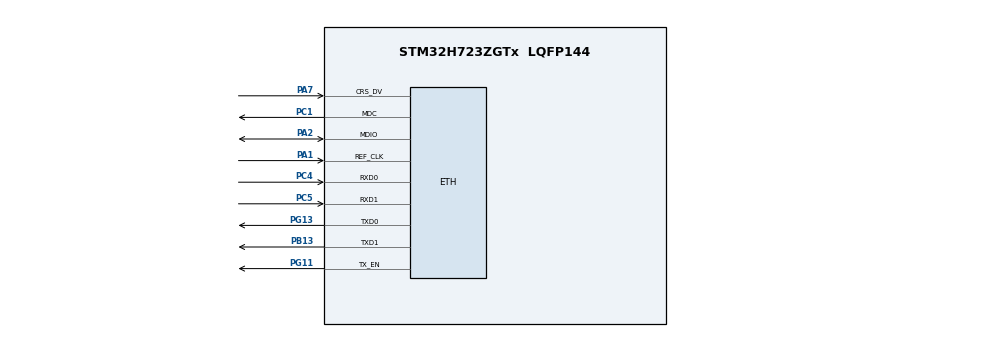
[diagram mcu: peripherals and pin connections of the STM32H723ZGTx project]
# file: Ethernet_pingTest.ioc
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CORTEX_M7.AccessPermission_S-Cortex_Memory_Protection_Unit_Region1_Settings_S=MPU_REGION_FULL_ACCESS
CORTEX_M7.BaseAddress_S-Cortex_Memory_Protection_Unit_Region1_Settings_S=0x30000000
CORTEX_M7.CPU_DCache=Enabled
CORTEX_M7.CPU_ICache=Enabled
CORTEX_M7.DisableExec_S-Cortex_Memory_Protection_Unit_Region1_Settings_S=MPU_INSTRUCTION_ACCESS_DISABLE
CORTEX_M7.Enable_S-Cortex_Memory_Protection_Unit_Region1_Settings_S=MPU_REGION_ENABLE
CORTEX_M7.Enable_Spec=__NULL
CORTEX_M7.IsShareable_S-Cortex_Memory_Protection_Unit_Region1_Settings_S=MPU_ACCESS_SHAREABLE
CORTEX_M7.Size_S-Cortex_Memory_Protection_Unit_Region1_Settings_S=MPU_REGION_SIZE_32KB
CORTEX_M7.TypeExtField_S-Cortex_Memory_Protection_Unit_Region1_Settings_S=MPU_TEX_LEVEL1
CORTEX_M7.default_mode_Activation=1
ETH.MediaInterface=HAL_ETH_RMII_MODE
LWIP.BSP.number=1
LWIP.IP_ADDRESS=192.168.001.020
LWIP.LWIP_DHCP=0
LWIP.NETMASK_ADDRESS=255.255.255.000
LWIP.Version=v2.1.2_Cube
LWIP0.BSP.STBoard=false
LWIP0.BSP.api=BSP_COMPONENT_DRIVER
LWIP0.BSP.component=LAN8742
LWIP0.BSP.instance=LAN8742
LWIP0.BSP.name=Driver_PHY
LWIP0.BSP.semaphore=S_LAN8742
LWIP0.BSP.solution=LAN8742
Mcu.Family=STM32H7
Mcu.Name=STM32H723ZGTx
Mcu.Package=LQFP144
NVIC.ETH_IRQn=true\:0\:0\:false\:false\:true\:true\:true\:true
NVIC.PriorityGroup=NVIC_PRIORITYGROUP_4
PA1.GPIO_Speed=GPIO_SPEED_FREQ_VERY_HIGH
PA1.Mode=RMII
PA1.Signal=ETH_REF_CLK
PA2.GPIO_Speed=GPIO_SPEED_FREQ_VERY_HIGH
PA2.Mode=RMII
PA2.Signal=ETH_MDIO
PA7.GPIO_Speed=GPIO_SPEED_FREQ_VERY_HIGH
PA7.Mode=RMII
PA7.Signal=ETH_CRS_DV
PB0.TagName=LD1
PB13.GPIO_Speed=GPIO_SPEED_FREQ_VERY_HIGH
PB13.Mode=RMII
PB13.Signal=ETH_TXD1
PB14.TagName=LD3
PC1.GPIO_Speed=GPIO_SPEED_FREQ_VERY_HIGH
PC1.Mode=RMII
PC1.Signal=ETH_MDC
PC13.TagName=BUTTON
PC4.GPIO_Speed=GPIO_SPEED_FREQ_VERY_HIGH
PC4.Mode=RMII
PC4.Signal=ETH_RXD0
PC5.GPIO_Speed=GPIO_SPEED_FREQ_VERY_HIGH
PC5.Mode=RMII
PC5.Signal=ETH_RXD1
PD8.TagName=VCP_TX
PD9.TagName=VCP_RX
PE1.TagName=LD2
PG11.GPIO_Speed=GPIO_SPEED_FREQ_VERY_HIGH
PG11.Mode=RMII
PG11.Signal=ETH_TX_EN
PG13.GPIO_Speed=GPIO_SPEED_FREQ_VERY_HIGH
PG13.Mode=RMII
PG13.Signal=ETH_TXD0
ProjectManager.HeapSize=0x200
ProjectManager.StackSize=0x400
ProjectManager.TargetToolchain=STM32CubeIDE
RCC.ADCFreq_Value=608000000
RCC.APB1Freq_Value=128000000
RCC.APB2Freq_Value=128000000
RCC.APB3Freq_Value=128000000
RCC.APB4Freq_Value=128000000
RCC.CortexFreq_Value=256000000
RCC.D1PPRE=RCC_APB3_DIV2
RCC.D2PPRE1=RCC_APB1_DIV2
RCC.D2PPRE2=RCC_APB2_DIV2
RCC.D3PPRE=RCC_APB4_DIV2
RCC.DIVM1=4
RCC.DIVM2=1
RCC.DIVN1=16
RCC.DIVN2=19
RCC.DIVP1=1
RCC.DIVQ1=4
RCC.HCLKFreq_Value=256000000
RCC.HSE_VALUE=8000000
RCC.PLLFRACN=0
RCC.SYSCLKFreq_VALUE=256000000
RCC.SYSCLKSource=RCC_SYSCLKSOURCE_PLLCLK
RCC.USBCLockSelection=RCC_USBCLKSOURCE_HSI48
RCC.USBFreq_Value=48000000
VP_LWIP_VS_Enabled.Mode=Enabled
VP_MEMORYMAP_VS_MEMORYMAP.Mode=CurAppReg
board=NUCLEO-H723ZG

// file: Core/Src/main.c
/* USER CODE BEGIN Header */
/**
  ******************************************************************************
  * @file           : main.c
  * @brief          : Main program body
  ******************************************************************************
  * @attention
  *
  * Copyright (c) 2026 STMicroelectronics.
  * All rights reserved.
  *
  * This software is licensed under terms that can be found in the LICENSE file
  * in the root directory of this software component.
  * If no LICENSE file comes with this software, it is provided AS-IS.
  *
  ******************************************************************************
  */
/* USER CODE END Header */
#include "main.h"
#include "lwip.h"
#include "gpio.h"

void SystemClock_Config(void);
static void MPU_Config(void);

int main(void)
{

  /* MPU Configuration--------------------------------------------------------*/
  MPU_Config();

  /* Enable the CPU Cache */
  /* Enable D2 SRAM clocks */
  __HAL_RCC_D2SRAM1_CLK_ENABLE();
  __HAL_RCC_D2SRAM2_CLK_ENABLE();
  /* Enable I-Cache---------------------------------------------------------*/
  SCB_EnableICache();

  /* Enable D-Cache---------------------------------------------------------*/
  SCB_EnableDCache();

  /* MCU Configuration--------------------------------------------------------*/

  /* Reset of all peripherals, Initializes the Flash interface and the Systick. */
  HAL_Init();

  /* USER CODE BEGIN Init */
//  volatile uint32_t *test_address =
//      (volatile uint32_t *)0x30005000;
//
//  *test_address = 0x12345678;
//
//  volatile uint32_t read_back = *test_address;
  /* USER CODE END Init */

  /* Configure the system clock */
  SystemClock_Config();

  /* Initialize all configured peripherals */
  MX_GPIO_Init();
  MX_LWIP_Init();

  /* Infinite loop */
  while (1)
  {

    /* USER CODE BEGIN 3 */
	  MX_LWIP_Process();
  }
  /* USER CODE END 3 */
}

void SystemClock_Config(void)
{
  RCC_OscInitTypeDef RCC_OscInitStruct = {0};
  RCC_ClkInitTypeDef RCC_ClkInitStruct = {0};

  /** Supply configuration update enable
  */
  HAL_PWREx_ConfigSupply(PWR_LDO_SUPPLY);

  /** Configure the main internal regulator output voltage
  */
  __HAL_PWR_VOLTAGESCALING_CONFIG(PWR_REGULATOR_VOLTAGE_SCALE0);

  while(!__HAL_PWR_GET_FLAG(PWR_FLAG_VOSRDY)) {}

  /** Initializes the RCC Oscillators according to the specified parameters
  * in the RCC_OscInitTypeDef structure.
  */
  RCC_OscInitStruct.OscillatorType = RCC_OSCILLATORTYPE_HSI;
  RCC_OscInitStruct.HSIState = RCC_HSI_DIV1;
  RCC_OscInitStruct.HSICalibrationValue = 64;
  RCC_OscInitStruct.PLL.PLLState = RCC_PLL_ON;
  RCC_OscInitStruct.PLL.PLLSource = RCC_PLLSOURCE_HSI;
  RCC_OscInitStruct.PLL.PLLM = 4;
  RCC_OscInitStruct.PLL.PLLN = 16;
  RCC_OscInitStruct.PLL.PLLP = 1;
  RCC_OscInitStruct.PLL.PLLQ = 4;
  RCC_OscInitStruct.PLL.PLLR = 2;
  RCC_OscInitStruct.PLL.PLLRGE = RCC_PLL1VCIRANGE_3;
  RCC_OscInitStruct.PLL.PLLVCOSEL = RCC_PLL1VCOWIDE;
  RCC_OscInitStruct.PLL.PLLFRACN = 0;
  if (HAL_RCC_OscConfig(&RCC_OscInitStruct) != HAL_OK)
  {
    Error_Handler();
  }

  /** Initializes the CPU, AHB and APB buses clocks
  */
  RCC_ClkInitStruct.ClockType = RCC_CLOCKTYPE_HCLK|RCC_CLOCKTYPE_SYSCLK
                              |RCC_CLOCKTYPE_PCLK1|RCC_CLOCKTYPE_PCLK2
                              |RCC_CLOCKTYPE_D3PCLK1|RCC_CLOCKTYPE_D1PCLK1;
  RCC_ClkInitStruct.SYSCLKSource = RCC_SYSCLKSOURCE_PLLCLK;
  RCC_ClkInitStruct.SYSCLKDivider = RCC_SYSCLK_DIV1;
  RCC_ClkInitStruct.AHBCLKDivider = RCC_HCLK_DIV1;
  RCC_ClkInitStruct.APB3CLKDivider = RCC_APB3_DIV2;
  RCC_ClkInitStruct.APB1CLKDivider = RCC_APB1_DIV2;
  RCC_ClkInitStruct.APB2CLKDivider = RCC_APB2_DIV2;
  RCC_ClkInitStruct.APB4CLKDivider = RCC_APB4_DIV2;

  if (HAL_RCC_ClockConfig(&RCC_ClkInitStruct, FLASH_LATENCY_3) != HAL_OK)
  {
    Error_Handler();
  }
}

 /* MPU Configuration */

void MPU_Config(void)
{
  MPU_Region_InitTypeDef MPU_InitStruct = {0};

  /* Disables the MPU */
  HAL_MPU_Disable();

  /** Initializes and configures the Region and the memory to be protected
  */
  MPU_InitStruct.Enable = MPU_REGION_ENABLE;
  MPU_InitStruct.BaseAddress = 0x30000000;
  MPU_InitStruct.Size = MPU_REGION_SIZE_32KB;
  MPU_InitStruct.SubRegionDisable = 0x0;
  MPU_InitStruct.TypeExtField = MPU_TEX_LEVEL1;
  MPU_InitStruct.AccessPermission = MPU_REGION_FULL_ACCESS;
  MPU_InitStruct.DisableExec = MPU_INSTRUCTION_ACCESS_DISABLE;
  MPU_InitStruct.IsShareable = MPU_ACCESS_SHAREABLE;
  MPU_InitStruct.IsCacheable = MPU_ACCESS_NOT_CACHEABLE;
  MPU_InitStruct.IsBufferable = MPU_ACCESS_NOT_BUFFERABLE;

  HAL_MPU_ConfigRegion(&MPU_InitStruct);
  /* Enables the MPU */
  HAL_MPU_Enable(MPU_PRIVILEGED_DEFAULT);

}

void Error_Handler(void)
{
  __disable_irq();
  while (1)
  {
  }
}
